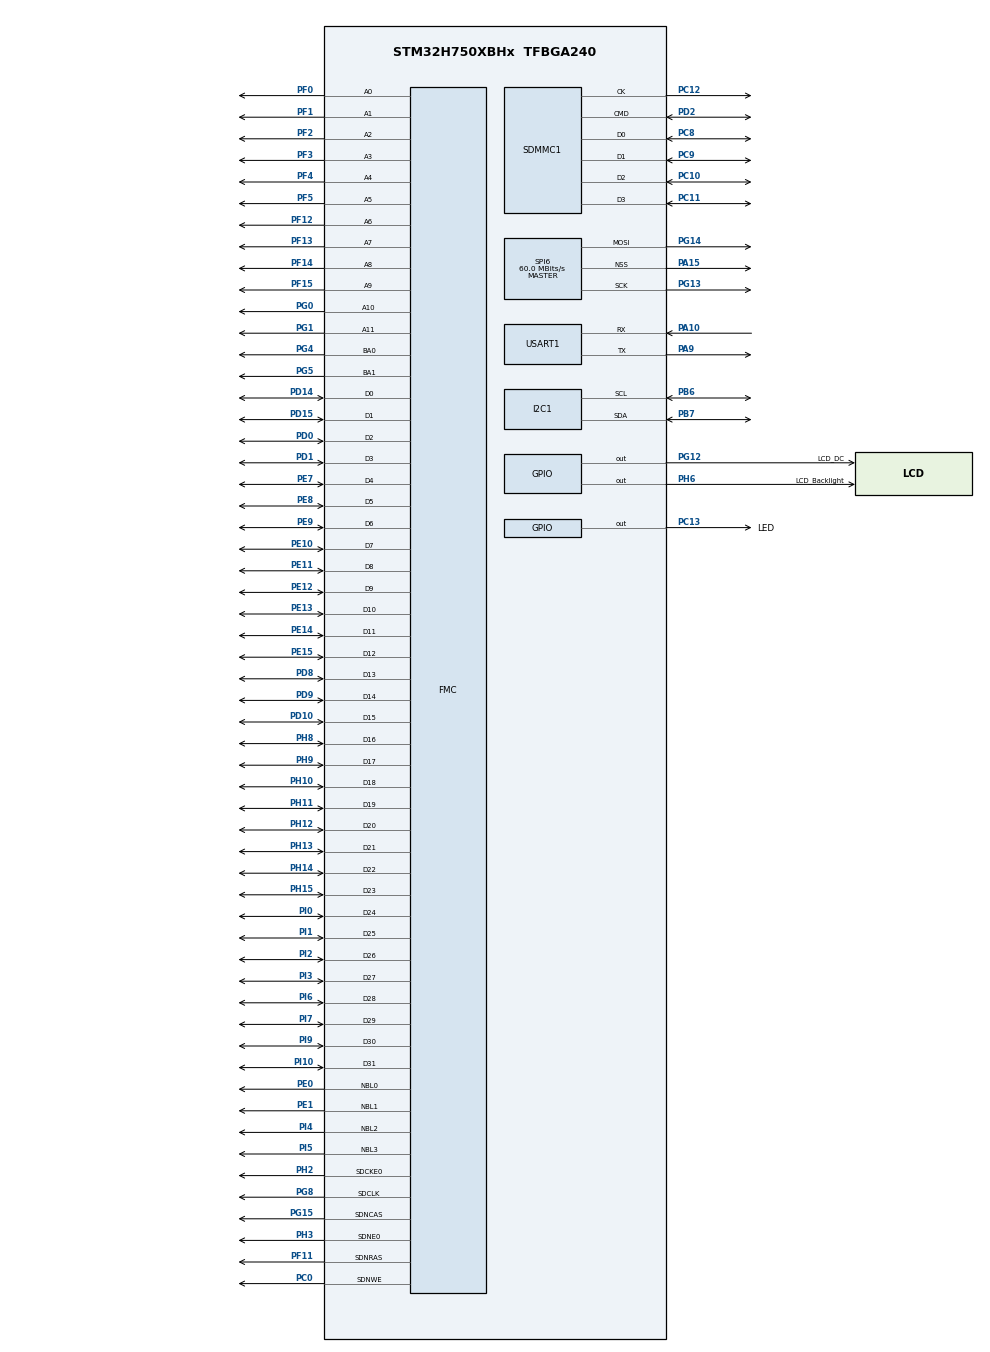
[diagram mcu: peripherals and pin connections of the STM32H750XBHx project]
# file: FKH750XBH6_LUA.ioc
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CORTEX_M7.AccessPermission_S-Cortex_Memory_Protection_Unit_Region1_Settings_S=MPU_REGION_FULL_ACCESS
CORTEX_M7.AccessPermission_S-Cortex_Memory_Protection_Unit_Region2_Settings_S=MPU_REGION_FULL_ACCESS
CORTEX_M7.AccessPermission_S-Cortex_Memory_Protection_Unit_Region3_Settings_S=MPU_REGION_FULL_ACCESS
CORTEX_M7.AccessPermission_Spec=MPU_REGION_FULL_ACCESS
CORTEX_M7.BaseAddress_S-Cortex_Memory_Protection_Unit_Region1_Settings_S=0x24000000
CORTEX_M7.BaseAddress_S-Cortex_Memory_Protection_Unit_Region2_Settings_S=0x90000000
CORTEX_M7.BaseAddress_S-Cortex_Memory_Protection_Unit_Region3_Settings_S=0xC0000000
CORTEX_M7.BaseAddress_Spec=0x20000000
CORTEX_M7.CPU_DCache=Enabled
CORTEX_M7.CPU_ICache=Enabled
CORTEX_M7.DisableExec_S-Cortex_Memory_Protection_Unit_Region2_Settings_S=MPU_INSTRUCTION_ACCESS_ENABLE
CORTEX_M7.DisableExec_Spec=MPU_INSTRUCTION_ACCESS_ENABLE
CORTEX_M7.Enable_S-Cortex_Memory_Protection_Unit_Region1_Settings_S=MPU_REGION_ENABLE
CORTEX_M7.Enable_S-Cortex_Memory_Protection_Unit_Region2_Settings_S=MPU_REGION_ENABLE
CORTEX_M7.Enable_S-Cortex_Memory_Protection_Unit_Region3_Settings_S=MPU_REGION_ENABLE
CORTEX_M7.IsBufferable_S-Cortex_Memory_Protection_Unit_Region1_Settings_S=MPU_ACCESS_BUFFERABLE
CORTEX_M7.IsBufferable_S-Cortex_Memory_Protection_Unit_Region2_Settings_S=MPU_ACCESS_NOT_BUFFERABLE
CORTEX_M7.IsBufferable_S-Cortex_Memory_Protection_Unit_Region3_Settings_S=MPU_ACCESS_BUFFERABLE
CORTEX_M7.IsBufferable_Spec=MPU_ACCESS_BUFFERABLE
CORTEX_M7.IsCacheable_S-Cortex_Memory_Protection_Unit_Region1_Settings_S=MPU_ACCESS_CACHEABLE
CORTEX_M7.IsCacheable_S-Cortex_Memory_Protection_Unit_Region2_Settings_S=MPU_ACCESS_CACHEABLE
CORTEX_M7.IsCacheable_S-Cortex_Memory_Protection_Unit_Region3_Settings_S=MPU_ACCESS_CACHEABLE
CORTEX_M7.IsCacheable_Spec=MPU_ACCESS_NOT_CACHEABLE
CORTEX_M7.IsShareable_S-Cortex_Memory_Protection_Unit_Region1_Settings_S=MPU_ACCESS_SHAREABLE
CORTEX_M7.IsShareable_S-Cortex_Memory_Protection_Unit_Region2_Settings_S=MPU_ACCESS_NOT_SHAREABLE
CORTEX_M7.IsShareable_S-Cortex_Memory_Protection_Unit_Region3_Settings_S=MPU_ACCESS_SHAREABLE
CORTEX_M7.IsShareable_Spec=MPU_ACCESS_NOT_SHAREABLE
CORTEX_M7.Size_S-Cortex_Memory_Protection_Unit_Region1_Settings_S=MPU_REGION_SIZE_512KB
CORTEX_M7.Size_S-Cortex_Memory_Protection_Unit_Region2_Settings_S=MPU_REGION_SIZE_32MB
CORTEX_M7.Size_S-Cortex_Memory_Protection_Unit_Region3_Settings_S=MPU_REGION_SIZE_32MB
CORTEX_M7.Size_Spec=MPU_REGION_SIZE_128KB
CORTEX_M7.SubRegionDisable_Spec=0x00
CORTEX_M7.TypeExtField_S-Cortex_Memory_Protection_Unit_Region1_Settings_S=MPU_TEX_LEVEL1
CORTEX_M7.TypeExtField_S-Cortex_Memory_Protection_Unit_Region3_Settings_S=MPU_TEX_LEVEL1
CORTEX_M7.TypeExtField_Spec=MPU_TEX_LEVEL1
CORTEX_M7.default_mode_Activation=1
Dma.Request0=USART1_RX
Dma.Request1=USART1_TX
Dma.USART1_RX.0.Direction=DMA_PERIPH_TO_MEMORY
Dma.USART1_RX.0.EventEnable=DISABLE
Dma.USART1_RX.0.FIFOMode=DMA_FIFOMODE_DISABLE
Dma.USART1_RX.0.Instance=DMA1_Stream0
Dma.USART1_RX.0.MemDataAlignment=DMA_MDATAALIGN_BYTE
Dma.USART1_RX.0.MemInc=DMA_MINC_ENABLE
Dma.USART1_RX.0.Mode=DMA_NORMAL
Dma.USART1_RX.0.PeriphDataAlignment=DMA_PDATAALIGN_BYTE
Dma.USART1_RX.0.PeriphInc=DMA_PINC_DISABLE
Dma.USART1_RX.0.Polarity=HAL_DMAMUX_REQ_GEN_RISING
Dma.USART1_RX.0.Priority=DMA_PRIORITY_HIGH
Dma.USART1_RX.0.RequestNumber=1
Dma.USART1_RX.0.SignalID=NONE
Dma.USART1_RX.0.SyncEnable=DISABLE
Dma.USART1_RX.0.SyncPolarity=HAL_DMAMUX_SYNC_NO_EVENT
Dma.USART1_RX.0.SyncRequestNumber=1
Dma.USART1_RX.0.SyncSignalID=NONE
Dma.USART1_TX.1.Direction=DMA_MEMORY_TO_PERIPH
Dma.USART1_TX.1.EventEnable=DISABLE
Dma.USART1_TX.1.FIFOMode=DMA_FIFOMODE_DISABLE
Dma.USART1_TX.1.Instance=DMA1_Stream1
Dma.USART1_TX.1.MemDataAlignment=DMA_MDATAALIGN_BYTE
Dma.USART1_TX.1.MemInc=DMA_MINC_ENABLE
Dma.USART1_TX.1.Mode=DMA_NORMAL
Dma.USART1_TX.1.PeriphDataAlignment=DMA_PDATAALIGN_BYTE
Dma.USART1_TX.1.PeriphInc=DMA_PINC_DISABLE
Dma.USART1_TX.1.Polarity=HAL_DMAMUX_REQ_GEN_RISING
Dma.USART1_TX.1.Priority=DMA_PRIORITY_HIGH
Dma.USART1_TX.1.RequestNumber=1
Dma.USART1_TX.1.SignalID=NONE
Dma.USART1_TX.1.SyncEnable=DISABLE
Dma.USART1_TX.1.SyncPolarity=HAL_DMAMUX_SYNC_NO_EVENT
Dma.USART1_TX.1.SyncRequestNumber=1
Dma.USART1_TX.1.SyncSignalID=NONE
FATFS._CODE_PAGE=437
FATFS._FS_RPATH=2
FATFS._MAX_SS=4096
FATFS._USE_LFN=2
FMC.CASLatency1=FMC_SDRAM_CAS_LATENCY_3
FMC.ColumnBitsNumber1=FMC_SDRAM_COLUMN_BITS_NUM_9
FMC.ExitSelfRefreshDelay1=6
FMC.LoadToActiveDelay1=2
FMC.RCDDelay1=2
FMC.RPDelay1=2
FMC.RPDelay2=2
FMC.ReadBurst1=FMC_SDRAM_RBURST_ENABLE
FMC.ReadBurst2=FMC_SDRAM_RBURST_ENABLE
FMC.RowCycleDelay1=7
FMC.RowCycleDelay2=7
FMC.SDClockPeriod1=FMC_SDRAM_CLOCK_PERIOD_2
FMC.SDClockPeriod2=FMC_SDRAM_CLOCK_PERIOD_2
FMC.SelfRefreshTime1=4
FMC.WriteRecoveryTime1=3
FREERTOS.HEAP_NUMBER=5
FREERTOS.Tasks01=defaultTask,24,128,StartDefaultTask,Default,NULL,Dynamic,NULL,NULL;LUA_ProcessTask,24,512,LUA_ProcessTask_Handle,Default,NULL,Dynamic,NULL,NULL
FREERTOS.configENABLE_FPU=1
FREERTOS.configGENERATE_RUN_TIME_STATS=1
FREERTOS.configRECORD_STACK_HIGH_ADDRESS=1
I2C1.Timing=0x307075B1
Mcu.Family=STM32H7
Mcu.Name=STM32H750XBHx
Mcu.Package=TFBGA240
Mdma.MDMA_Channel0.Request0=SDMMC1_END_DATA
Mdma.MDMA_Channel0.RequestsNb=1
Mdma.MDMA_Channel0.SDMMC1_END_DATA.0.BlockCount=0
Mdma.MDMA_Channel0.SDMMC1_END_DATA.0.BlockDataLength=0
Mdma.MDMA_Channel0.SDMMC1_END_DATA.0.BufferTransferLength=1
Mdma.MDMA_Channel0.SDMMC1_END_DATA.0.CircularMode=MDMA_LINEAR_LIST
Mdma.MDMA_Channel0.SDMMC1_END_DATA.0.DataAlignment=MDMA_DATAALIGN_PACKENABLE
Mdma.MDMA_Channel0.SDMMC1_END_DATA.0.DestBlockAddressOffset=0
Mdma.MDMA_Channel0.SDMMC1_END_DATA.0.DestBurst=MDMA_DEST_BURST_SINGLE
Mdma.MDMA_Channel0.SDMMC1_END_DATA.0.DestDataSize=MDMA_DEST_DATASIZE_BYTE
Mdma.MDMA_Channel0.SDMMC1_END_DATA.0.DestinationInc=MDMA_DEST_INC_BYTE
Mdma.MDMA_Channel0.SDMMC1_END_DATA.0.DstAddress=0
Mdma.MDMA_Channel0.SDMMC1_END_DATA.0.Endianness=MDMA_LITTLE_ENDIANNESS_PRESERVE
Mdma.MDMA_Channel0.SDMMC1_END_DATA.0.Instance=MDMA_Channel0
Mdma.MDMA_Channel0.SDMMC1_END_DATA.0.MaskAddress=0
Mdma.MDMA_Channel0.SDMMC1_END_DATA.0.MaskData=0
Mdma.MDMA_Channel0.SDMMC1_END_DATA.0.Priority=MDMA_PRIORITY_MEDIUM
Mdma.MDMA_Channel0.SDMMC1_END_DATA.0.Rank=First
Mdma.MDMA_Channel0.SDMMC1_END_DATA.0.SourceBlockAddressOffset=0
Mdma.MDMA_Channel0.SDMMC1_END_DATA.0.SourceBurst=MDMA_SOURCE_BURST_SINGLE
Mdma.MDMA_Channel0.SDMMC1_END_DATA.0.SourceDataSize=MDMA_SRC_DATASIZE_BYTE
Mdma.MDMA_Channel0.SDMMC1_END_DATA.0.SourceInc=MDMA_SRC_INC_BYTE
Mdma.MDMA_Channel0.SDMMC1_END_DATA.0.SrcAddress=0
Mdma.MDMA_Channel0.SDMMC1_END_DATA.0.TransferTriggerMode=MDMA_BUFFER_TRANSFER
Mdma.RequestSet0=MDMA_Channel0
Mdma.RequestSetsNb=1
NVIC.DMA1_Stream0_IRQn=true\:5\:0\:false\:false\:true\:true\:false\:true\:true
NVIC.DMA1_Stream1_IRQn=true\:5\:0\:false\:false\:true\:true\:false\:true\:true
NVIC.MDMA_IRQn=true\:5\:0\:false\:false\:true\:false\:false\:true\:true
NVIC.PriorityGroup=NVIC_PRIORITYGROUP_4
NVIC.SDMMC1_IRQn=true\:5\:0\:false\:false\:true\:true\:true\:true\:true
NVIC.TIM17_IRQn=true\:15\:0\:false\:false\:true\:false\:false\:true\:true
NVIC.TimeBase=TIM17_IRQn
NVIC.TimeBaseIP=TIM17
NVIC.USART1_IRQn=true\:5\:0\:false\:false\:true\:true\:false\:true\:true
PA10.GPIO_Speed=GPIO_SPEED_FREQ_VERY_HIGH
PA10.Mode=Asynchronous
PA10.Signal=USART1_RX
PA15\ (JTDI).GPIO_Speed=GPIO_SPEED_FREQ_VERY_HIGH
PA15\ (JTDI).Mode=NSS_Signal_Hard_Output
PA15\ (JTDI).Signal=SPI6_NSS
PA9.GPIO_Speed=GPIO_SPEED_FREQ_VERY_HIGH
PA9.Mode=Asynchronous
PA9.Signal=USART1_TX
PB6.GPIO_Speed=GPIO_SPEED_FREQ_VERY_HIGH
PB6.Mode=I2C
PB6.Signal=I2C1_SCL
PB7.GPIO_Speed=GPIO_SPEED_FREQ_VERY_HIGH
PB7.Mode=I2C
PB7.Signal=I2C1_SDA
PC0.Signal=FMC_SDNWE
PC10.Mode=SD_4_bits_Wide_bus
PC10.Signal=SDMMC1_D2
PC11.Mode=SD_4_bits_Wide_bus
PC11.Signal=SDMMC1_D3
PC12.Mode=SD_4_bits_Wide_bus
PC12.Signal=SDMMC1_CK
PC13.GPIO_Label=LED
PC13.PinState=GPIO_PIN_SET
PC13.Signal=GPIO_Output
PC14-OSC32_IN\ (OSC32_IN).Mode=LSE-External-Oscillator
PC14-OSC32_IN\ (OSC32_IN).Signal=RCC_OSC32_IN
PC15-OSC32_OUT\ (OSC32_OUT).Mode=LSE-External-Oscillator
PC15-OSC32_OUT\ (OSC32_OUT).Signal=RCC_OSC32_OUT
PC8.Mode=SD_4_bits_Wide_bus
PC8.Signal=SDMMC1_D0
PC9.Mode=SD_4_bits_Wide_bus
PC9.Signal=SDMMC1_D1
PD0.Signal=FMC_D2_DA2
PD1.Signal=FMC_D3_DA3
PD10.Signal=FMC_D15_DA15
PD14.Signal=FMC_D0_DA0
PD15.Signal=FMC_D1_DA1
PD2.Mode=SD_4_bits_Wide_bus
PD2.Signal=SDMMC1_CMD
PD8.Signal=FMC_D13_DA13
PD9.Signal=FMC_D14_DA14
PE0.Signal=FMC_NBL0
PE1.Signal=FMC_NBL1
PE10.Signal=FMC_D7_DA7
PE11.Signal=FMC_D8_DA8
PE12.Signal=FMC_D9_DA9
PE13.Signal=FMC_D10_DA10
PE14.Signal=FMC_D11_DA11
PE15.Signal=FMC_D12_DA12
PE7.Signal=FMC_D4_DA4
PE8.Signal=FMC_D5_DA5
PE9.Signal=FMC_D6_DA6
PF0.Signal=FMC_A0
PF1.Signal=FMC_A1
PF10.GPIO_Speed=GPIO_SPEED_FREQ_VERY_HIGH
PF10.Signal=QUADSPI_CLK
PF11.Signal=FMC_SDNRAS
PF12.Signal=FMC_A6
PF13.Signal=FMC_A7
PF14.Signal=FMC_A8
PF15.Signal=FMC_A9
PF2.Signal=FMC_A2
PF3.Signal=FMC_A3
PF4.Signal=FMC_A4
PF5.Signal=FMC_A5
PF6.GPIO_Speed=GPIO_SPEED_FREQ_VERY_HIGH
PF6.Signal=QUADSPI_BK1_IO3
PF7.GPIO_Speed=GPIO_SPEED_FREQ_VERY_HIGH
PF7.Signal=QUADSPI_BK1_IO2
PF8.GPIO_Speed=GPIO_SPEED_FREQ_VERY_HIGH
PF8.Signal=QUADSPI_BK1_IO0
PF9.GPIO_Speed=GPIO_SPEED_FREQ_VERY_HIGH
PF9.Signal=QUADSPI_BK1_IO1
PG0.Signal=FMC_A10
PG1.Signal=FMC_A11
PG12.GPIO_Label=LCD_DC
PG12.GPIO_Speed=GPIO_SPEED_FREQ_VERY_HIGH
PG12.Signal=GPIO_Output
PG13.GPIO_Speed=GPIO_SPEED_FREQ_VERY_HIGH
PG13.Mode=TX_Only_Simplex_Unidirect_Master
PG13.Signal=SPI6_SCK
PG14.GPIO_Speed=GPIO_SPEED_FREQ_VERY_HIGH
PG14.Mode=TX_Only_Simplex_Unidirect_Master
PG14.Signal=SPI6_MOSI
PG15.Signal=FMC_SDNCAS
PG4.Signal=FMC_A14_BA0
PG5.Signal=FMC_A15_BA1
PG6.GPIO_Speed=GPIO_SPEED_FREQ_VERY_HIGH
PG6.Signal=QUADSPI_BK1_NCS
PG8.Signal=FMC_SDCLK
PH0-OSC_IN\ (PH0).Mode=HSE-External-Oscillator
PH0-OSC_IN\ (PH0).Signal=RCC_OSC_IN
PH1-OSC_OUT\ (PH1).Mode=HSE-External-Oscillator
PH1-OSC_OUT\ (PH1).Signal=RCC_OSC_OUT
PH10.Signal=FMC_D18
PH11.Signal=FMC_D19
PH12.Signal=FMC_D20
PH13.Signal=FMC_D21
PH14.Signal=FMC_D22
PH15.Signal=FMC_D23
PH2.Mode=SdramChipSelect1_1
PH2.Signal=FMC_SDCKE0
PH3.Mode=SdramChipSelect1_1
PH3.Signal=FMC_SDNE0
PH6.GPIO_Label=LCD_Backlight
PH6.GPIO_Speed=GPIO_SPEED_FREQ_MEDIUM
PH6.Signal=GPIO_Output
PH8.Signal=FMC_D16
PH9.Signal=FMC_D17
PI0.Signal=FMC_D24
PI1.Signal=FMC_D25
PI10.Signal=FMC_D31
PI2.Signal=FMC_D26
PI3.Signal=FMC_D27
PI4.Signal=FMC_NBL2
PI5.Signal=FMC_NBL3
PI6.Signal=FMC_D28
PI7.Signal=FMC_D29
PI9.Signal=FMC_D30
ProjectManager.HeapSize=0x2000
ProjectManager.StackSize=0x400
ProjectManager.TargetToolchain=CMake
RCC.ADCFreq_Value=320000000
RCC.APB1Freq_Value=120000000
RCC.APB2Freq_Value=120000000
RCC.APB3Freq_Value=120000000
RCC.APB4Freq_Value=120000000
RCC.CortexFreq_Value=480000000
RCC.D1PPRE=RCC_APB3_DIV2
RCC.D2PPRE1=RCC_APB1_DIV2
RCC.D2PPRE2=RCC_APB2_DIV2
RCC.D3PPRE=RCC_APB4_DIV2
RCC.DIVM1=5
RCC.DIVM2=5
RCC.DIVM3=5
RCC.DIVN1=192
RCC.DIVN2=128
RCC.DIVN3=128
RCC.DIVQ1=4
RCC.HCLKFreq_Value=240000000
RCC.HPRE=RCC_HCLK_DIV2
RCC.PLLSourceVirtual=RCC_PLLSOURCE_HSE
RCC.SYSCLKFreq_VALUE=480000000
RCC.SYSCLKSource=RCC_SYSCLKSOURCE_PLLCLK
RCC.USBFreq_Value=240000000
SDMMC1.ClockDiv=6
SH.FMC_A0.0=FMC_A0,12b-sda1
SH.FMC_A1.0=FMC_A1,12b-sda1
SH.FMC_A10.0=FMC_A10,12b-sda1
SH.FMC_A11.0=FMC_A11,12b-sda1
SH.FMC_A14_BA0.0=FMC_BA0,FourSdramBanks1
SH.FMC_A15_BA1.0=FMC_BA1,FourSdramBanks1
SH.FMC_A2.0=FMC_A2,12b-sda1
SH.FMC_A3.0=FMC_A3,12b-sda1
SH.FMC_A4.0=FMC_A4,12b-sda1
SH.FMC_A5.0=FMC_A5,12b-sda1
SH.FMC_A6.0=FMC_A6,12b-sda1
SH.FMC_A7.0=FMC_A7,12b-sda1
SH.FMC_A8.0=FMC_A8,12b-sda1
SH.FMC_A9.0=FMC_A9,12b-sda1
SH.FMC_D0_DA0.0=FMC_D0,sd-32b-d1
SH.FMC_D10_DA10.0=FMC_D10,sd-32b-d1
SH.FMC_D11_DA11.0=FMC_D11,sd-32b-d1
SH.FMC_D12_DA12.0=FMC_D12,sd-32b-d1
SH.FMC_D13_DA13.0=FMC_D13,sd-32b-d1
SH.FMC_D14_DA14.0=FMC_D14,sd-32b-d1
SH.FMC_D15_DA15.0=FMC_D15,sd-32b-d1
SH.FMC_D16.0=FMC_D16,sd-32b-d1
SH.FMC_D17.0=FMC_D17,sd-32b-d1
SH.FMC_D18.0=FMC_D18,sd-32b-d1
SH.FMC_D19.0=FMC_D19,sd-32b-d1
SH.FMC_D1_DA1.0=FMC_D1,sd-32b-d1
SH.FMC_D20.0=FMC_D20,sd-32b-d1
SH.FMC_D21.0=FMC_D21,sd-32b-d1
SH.FMC_D22.0=FMC_D22,sd-32b-d1
SH.FMC_D23.0=FMC_D23,sd-32b-d1
SH.FMC_D24.0=FMC_D24,sd-32b-d1
SH.FMC_D25.0=FMC_D25,sd-32b-d1
SH.FMC_D26.0=FMC_D26,sd-32b-d1
SH.FMC_D27.0=FMC_D27,sd-32b-d1
SH.FMC_D28.0=FMC_D28,sd-32b-d1
SH.FMC_D29.0=FMC_D29,sd-32b-d1
SH.FMC_D2_DA2.0=FMC_D2,sd-32b-d1
SH.FMC_D30.0=FMC_D30,sd-32b-d1
SH.FMC_D31.0=FMC_D31,sd-32b-d1
SH.FMC_D3_DA3.0=FMC_D3,sd-32b-d1
SH.FMC_D4_DA4.0=FMC_D4,sd-32b-d1
SH.FMC_D5_DA5.0=FMC_D5,sd-32b-d1
SH.FMC_D6_DA6.0=FMC_D6,sd-32b-d1
SH.FMC_D7_DA7.0=FMC_D7,sd-32b-d1
SH.FMC_D8_DA8.0=FMC_D8,sd-32b-d1
SH.FMC_D9_DA9.0=FMC_D9,sd-32b-d1
SH.FMC_NBL0.0=FMC_NBL0,Sd4ByteEnable1
SH.FMC_NBL1.0=FMC_NBL1,Sd4ByteEnable1
SH.FMC_NBL2.0=FMC_NBL2,Sd4ByteEnable1
SH.FMC_NBL3.0=FMC_NBL3,Sd4ByteEnable1
SH.FMC_SDCLK.0=FMC_SDCLK,12b-sda1
SH.FMC_SDNCAS.0=FMC_SDNCAS,12b-sda1
SH.FMC_SDNRAS.0=FMC_SDNRAS,12b-sda1
SH.FMC_SDNWE.0=FMC_SDNWE,12b-sda1
SPI6.CalculateBaudRate=60.0 MBits/s
SPI6.DataSize=SPI_DATASIZE_8BIT
SPI6.Direction=SPI_DIRECTION_2LINES_TXONLY
SPI6.FifoThreshold=SPI_FIFO_THRESHOLD_02DATA
SPI6.Mode=SPI_MODE_MASTER
SPI6.VirtualNSS=VM_NSSHARD
SPI6.VirtualType=VM_MASTER
USART1.VirtualMode-Asynchronous=VM_ASYNC
VP_FATFS_VS_SDIO.Mode=SDIO
VP_FREERTOS_VS_CMSIS_V2.Mode=CMSIS_V2
VP_MEMORYMAP_VS_MEMORYMAP.Mode=CurAppReg
VP_SYS_VS_tim17.Mode=TIM17
board=custom

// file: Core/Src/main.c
/* USER CODE BEGIN Header */
/**
  ******************************************************************************
  * @file           : main.c
  * @brief          : Main program body
  ******************************************************************************
  * @attention
  *
  * Copyright (c) 2025 STMicroelectronics.
  * All rights reserved.
  *
  * This software is licensed under terms that can be found in the LICENSE file
  * in the root directory of this software component.
  * If no LICENSE file comes with this software, it is provided AS-IS.
  *
  ******************************************************************************
  */
/* USER CODE END Header */
#include "main.h"
#include "cmsis_os.h"
#include "dma.h"
#include "fatfs.h"
#include "i2c.h"
#include "mdma.h"
#include "sdmmc.h"
#include "spi.h"
#include "usart.h"
#include "gpio.h"
#include "fmc.h"

void SystemClock_Config(void);
static void MPU_Config(void);
void MX_FREERTOS_Init(void);

int main(void)
{

  /* USER CODE BEGIN 1 */
  __enable_irq();
  /* USER CODE END 1 */

  /* MPU Configuration--------------------------------------------------------*/
  MPU_Config();

  /* Enable the CPU Cache */

  /* Enable I-Cache---------------------------------------------------------*/
  SCB_EnableICache();

  /* Enable D-Cache---------------------------------------------------------*/
  SCB_EnableDCache();

  /* MCU Configuration--------------------------------------------------------*/

  /* Reset of all peripherals, Initializes the Flash interface and the Systick. */
  HAL_Init();

  /* Configure the system clock */
  SystemClock_Config();

  /* Initialize all configured peripherals */
  MX_GPIO_Init();
  MX_DMA_Init();
  MX_MDMA_Init();
  MX_USART1_UART_Init();
  MX_I2C1_Init();
  MX_SDMMC1_SD_Init();
  MX_SPI6_Init();
  MX_FATFS_Init();
  MX_FMC_Init();
  /* USER CODE BEGIN 2 */
  // if(QSPI_W25Qxx_MemoryMappedMode() != QSPI_W25Qxx_OK)
  //   Error_Handler();
  /* USER CODE END 2 */

  /* Init scheduler */
  osKernelInitialize();  /* Call init function for freertos objects (in cmsis_os2.c) */
  MX_FREERTOS_Init();

  /* Start scheduler */
  osKernelStart();

  /* We should never get here as control is now taken by the scheduler */

  /* Infinite loop */
  while (1)
  {

  }
}

void SystemClock_Config(void)
{
  RCC_OscInitTypeDef RCC_OscInitStruct = {0};
  RCC_ClkInitTypeDef RCC_ClkInitStruct = {0};

  /** Supply configuration update enable
  */
  HAL_PWREx_ConfigSupply(PWR_LDO_SUPPLY);

  /** Configure the main internal regulator output voltage
  */
  __HAL_PWR_VOLTAGESCALING_CONFIG(PWR_REGULATOR_VOLTAGE_SCALE0);

  while(!__HAL_PWR_GET_FLAG(PWR_FLAG_VOSRDY)) {}

  /** Initializes the RCC Oscillators according to the specified parameters
  * in the RCC_OscInitTypeDef structure.
  */
  RCC_OscInitStruct.OscillatorType = RCC_OSCILLATORTYPE_HSE;
  RCC_OscInitStruct.HSEState = RCC_HSE_ON;
  RCC_OscInitStruct.PLL.PLLState = RCC_PLL_ON;
  RCC_OscInitStruct.PLL.PLLSource = RCC_PLLSOURCE_HSE;
  RCC_OscInitStruct.PLL.PLLM = 5;
  RCC_OscInitStruct.PLL.PLLN = 192;
  RCC_OscInitStruct.PLL.PLLP = 2;
  RCC_OscInitStruct.PLL.PLLQ = 4;
  RCC_OscInitStruct.PLL.PLLR = 2;
  RCC_OscInitStruct.PLL.PLLRGE = RCC_PLL1VCIRANGE_2;
  RCC_OscInitStruct.PLL.PLLVCOSEL = RCC_PLL1VCOWIDE;
  RCC_OscInitStruct.PLL.PLLFRACN = 0;
  if (HAL_RCC_OscConfig(&RCC_OscInitStruct) != HAL_OK)
  {
    Error_Handler();
  }

  /** Initializes the CPU, AHB and APB buses clocks
  */
  RCC_ClkInitStruct.ClockType = RCC_CLOCKTYPE_HCLK|RCC_CLOCKTYPE_SYSCLK
                              |RCC_CLOCKTYPE_PCLK1|RCC_CLOCKTYPE_PCLK2
                              |RCC_CLOCKTYPE_D3PCLK1|RCC_CLOCKTYPE_D1PCLK1;
  RCC_ClkInitStruct.SYSCLKSource = RCC_SYSCLKSOURCE_PLLCLK;
  RCC_ClkInitStruct.SYSCLKDivider = RCC_SYSCLK_DIV1;
  RCC_ClkInitStruct.AHBCLKDivider = RCC_HCLK_DIV2;
  RCC_ClkInitStruct.APB3CLKDivider = RCC_APB3_DIV2;
  RCC_ClkInitStruct.APB1CLKDivider = RCC_APB1_DIV2;
  RCC_ClkInitStruct.APB2CLKDivider = RCC_APB2_DIV2;
  RCC_ClkInitStruct.APB4CLKDivider = RCC_APB4_DIV2;

  if (HAL_RCC_ClockConfig(&RCC_ClkInitStruct, FLASH_LATENCY_4) != HAL_OK)
  {
    Error_Handler();
  }
}

 /* MPU Configuration */

void MPU_Config(void)
{
  MPU_Region_InitTypeDef MPU_InitStruct = {0};

  /* Disables the MPU */
  HAL_MPU_Disable();

  /** Initializes and configures the Region and the memory to be protected
  */
  MPU_InitStruct.Enable = MPU_REGION_ENABLE;
  MPU_InitStruct.Number = MPU_REGION_NUMBER0;
  MPU_InitStruct.BaseAddress = 0x20000000;
  MPU_InitStruct.Size = MPU_REGION_SIZE_128KB;
  MPU_InitStruct.SubRegionDisable = 0x00;
  MPU_InitStruct.TypeExtField = MPU_TEX_LEVEL1;
  MPU_InitStruct.AccessPermission = MPU_REGION_FULL_ACCESS;
  MPU_InitStruct.DisableExec = MPU_INSTRUCTION_ACCESS_ENABLE;
  MPU_InitStruct.IsShareable = MPU_ACCESS_NOT_SHAREABLE;
  MPU_InitStruct.IsCacheable = MPU_ACCESS_NOT_CACHEABLE;
  MPU_InitStruct.IsBufferable = MPU_ACCESS_BUFFERABLE;

  HAL_MPU_ConfigRegion(&MPU_InitStruct);

  /** Initializes and configures the Region and the memory to be protected
  */
  MPU_InitStruct.Number = MPU_REGION_NUMBER1;
  MPU_InitStruct.BaseAddress = 0x24000000;
  MPU_InitStruct.Size = MPU_REGION_SIZE_512KB;
  MPU_InitStruct.SubRegionDisable = 0x0;
  MPU_InitStruct.IsShareable = MPU_ACCESS_SHAREABLE;
  MPU_InitStruct.IsCacheable = MPU_ACCESS_CACHEABLE;

  HAL_MPU_ConfigRegion(&MPU_InitStruct);

  /** Initializes and configures the Region and the memory to be protected
  */
  MPU_InitStruct.Number = MPU_REGION_NUMBER2;
  MPU_InitStruct.BaseAddress = 0x90000000;
  MPU_InitStruct.Size = MPU_REGION_SIZE_32MB;
  MPU_InitStruct.TypeExtField = MPU_TEX_LEVEL0;
  MPU_InitStruct.IsShareable = MPU_ACCESS_NOT_SHAREABLE;
  MPU_InitStruct.IsBufferable = MPU_ACCESS_NOT_BUFFERABLE;

  HAL_MPU_ConfigRegion(&MPU_InitStruct);

  /** Initializes and configures the Region and the memory to be protected
  */
  MPU_InitStruct.Number = MPU_REGION_NUMBER3;
  MPU_InitStruct.BaseAddress = 0xC0000000;
  MPU_InitStruct.TypeExtField = MPU_TEX_LEVEL1;
  MPU_InitStruct.IsShareable = MPU_ACCESS_SHAREABLE;
  MPU_InitStruct.IsBufferable = MPU_ACCESS_BUFFERABLE;

  HAL_MPU_ConfigRegion(&MPU_InitStruct);
  /* Enables the MPU */
  HAL_MPU_Enable(MPU_PRIVILEGED_DEFAULT);

}

void HAL_TIM_PeriodElapsedCallback(TIM_HandleTypeDef *htim)
{
  if (htim->Instance == TIM17)
  {
    HAL_IncTick();
  }
}

void Error_Handler(void)
{
  __disable_irq();
  while (1)
  {
  }
}

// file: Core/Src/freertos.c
/* USER CODE BEGIN Header */
/**
  ******************************************************************************
  * File Name          : freertos.c
  * Description        : Code for freertos applications
  ******************************************************************************
  * @attention
  *
  * Copyright (c) 2025 STMicroelectronics.
  * All rights reserved.
  *
  * This software is licensed under terms that can be found in the LICENSE file
  * in the root directory of this software component.
  * If no LICENSE file comes with this software, it is provided AS-IS.
  *
  ******************************************************************************
  */
/* USER CODE END Header */

#include "FreeRTOS.h"
#include "task.h"
#include "main.h"
#include "cmsis_os.h"

/* USER CODE BEGIN Includes */
#include "usart.h"
#include "sdmmc.h"
#include "terminal.h"
#include "uart_dyn_rx.h"
#include <stdlib.h>
#include <string.h>
#include <sys/_intsup.h>

#include "lua.h"
#include "lualib.h"
#include "portable.h"
#include "setjmp.h"
#include "fatfs.h"
#include "config.h"
// #include "embedded_lua.h"
#include "hardware_bindings.h"
#include "lua_file_execute.h"
#include "lua_fatfs.h"
#include "lua_display.h"
/* USER CODE END Includes */

/* USER CODE BEGIN PTD */
#define AUTO_MOUNT 1
#define AUTO_INIT_DISPLAY 1
/* USER CODE END PTD */

/* USER CODE BEGIN PD */
// #define DTCMRAM_ADDR       ((uint8_t*)0x20000000)
// #define DTCMRAM_SIZE       ((uint32_t)0x00010000)
#define AXIRAM_ADDR        ((uint8_t*)0x24002000)
#define AXIRAM_SIZE        ((uint32_t)0x00078000)
#define SDRAM_ADDR         ((uint8_t*)0xC0000000)
#define SDRAM_SIZE         ((uint32_t)0x02000000)
/* USER CODE END PD */

/* USER CODE BEGIN Variables */
// static jmp_buf g_lua_panic_jmp;

static HeapRegion_t HeapRAMRegions[]=
{
  // {DTCMRAM_ADDR, DTCMRAM_SIZE},
  {AXIRAM_ADDR, AXIRAM_SIZE},
  {SDRAM_ADDR, SDRAM_SIZE},
  {NULL,0}
};
/* USER CODE END Variables */
/* Definitions for defaultTask */
osThreadId_t defaultTaskHandle;
const osThreadAttr_t defaultTask_attributes = {
  .name = "defaultTask",
  .stack_size = 128 * 4,
  .priority = (osPriority_t) osPriorityNormal,
};
/* Definitions for LUA_ProcessTask */
osThreadId_t LUA_ProcessTaskHandle;
const osThreadAttr_t LUA_ProcessTask_attributes = {
  .name = "LUA_ProcessTask",
  .stack_size = 2048 * 4,
  .priority = (osPriority_t) osPriorityNormal,
};

/* USER CODE BEGIN FunctionPrototypes */
int lua_panic_handler(lua_State* L);
int safe_lua_execute(lua_State* L, const char* code, const char* cmd_name);

void FatFs_GetVolume(void);
void FatFS_FileList(char* path);
uint8_t FatFs_FileTest(void);
/* USER CODE END FunctionPrototypes */

void StartDefaultTask(void *argument);
void LUA_ProcessTask_Handle(void *argument);

void MX_FREERTOS_Init(void); /* (MISRA C 2004 rule 8.1) */

/* Hook prototypes */
void configureTimerForRunTimeStats(void);
unsigned long getRunTimeCounterValue(void);

/* USER CODE BEGIN 1 */
/* Functions needed when configGENERATE_RUN_TIME_STATS is on */
void configureTimerForRunTimeStats(void)
{
	/* 启用 DWT 功能 */
  CoreDebug->DEMCR |= CoreDebug_DEMCR_TRCENA_Msk;

  /* 重置并启用周期计数器 */
  DWT->CYCCNT = 0;
  DWT->CTRL |= DWT_CTRL_CYCCNTENA_Msk;
}

unsigned long getRunTimeCounterValue(void)
{
	/* 直接返回当前周期计数值 */
  return DWT->CYCCNT;
}
/* USER CODE END 1 */

void MX_FREERTOS_Init(void) {
  /* USER CODE BEGIN Init */
  vPortDefineHeapRegions(HeapRAMRegions);
  /* USER CODE END Init */

  /* Create the thread(s) */
  /* creation of defaultTask */
  defaultTaskHandle = osThreadNew(StartDefaultTask, NULL, &defaultTask_attributes);

  /* creation of LUA_ProcessTask */
  LUA_ProcessTaskHandle = osThreadNew(LUA_ProcessTask_Handle, NULL, &LUA_ProcessTask_attributes);

}

void StartDefaultTask(void *argument)
{
  /* USER CODE BEGIN StartDefaultTask */
  // safe_printf("\rThread run\n");
  void *axi_sram_ptr = pvPortMalloc(100);
  if(axi_sram_ptr) {
      safe_printf("\r\033[35mSRAM allocation test: PASS (0x%lX)\033[0m\r\n", axi_sram_ptr);
      vPortFree(axi_sram_ptr);
  } else {
      safe_printf("\r\033[31mSRAM allocation test: FAIL\033[0m\r\n");
  }
  void *sdram_ptr = pvPortMalloc(1024 * 1024);  // 1MB
  if(sdram_ptr) {
      safe_printf("\r\033[35mSDRAM allocation test: PASS (0x%lX)\033[0m\r\n", sdram_ptr);

      /* 验证确实在 SDRAM 地址范围内 */
      if((uint32_t)sdram_ptr >= (uint32_t)SDRAM_ADDR &&
         (uint32_t)sdram_ptr < (uint32_t)SDRAM_ADDR + SDRAM_SIZE) {
          safe_printf("\r\033[35mSDRAM address verification: PASS (0x%lX)\033[0m\r\n", sdram_ptr);
      } else {
          safe_printf("\r\033[35mSDRAM address verification: FAIL (0x%lX)\033[0m\r\n", sdram_ptr);
      }
      vPortFree(sdram_ptr);
  } else {
      safe_printf("\r\033[31mSDRAM allocation test: FAIL\033[0m\r\n");
  }
  /* Infinite loop */
  for(;;)
  {
    osDelay(1);
  }
  /* USER CODE END StartDefaultTask */
}

void LUA_ProcessTask_Handle(void *argument)
{
  /* USER CODE BEGIN LUA_ProcessTask_Handle */
  /* Infinite loop */
  // UART_DataPacket_t packet;
  char* received_cmd = NULL;
  lua_State* L;
  // 创建Lua虚拟机（这个任务的私有资源）
  L = luaL_newstate();
  if (L == NULL) {
    vTaskDelete(NULL);
  }
  luaL_openlibs(L); // 打开基础库
  // embedded_lua_init();
  hardware_bindings_init(L); // 注册你的硬件API
  fatfs_bindings_init(L);
  display_bindings_init(L);
  #if AUTO_INIT_DISPLAY
  lua_display_init(L);
  #endif
  #if AUTO_MOUNT
  if(lua_fatfs_mount(L) == 0)
    lua_auto_execute_startup(L);
    // FatFs_FileTest();
  #endif
  Terminal_Init();
  // UART_Dynamic_Receive_Init();
  // safe_printf("\033[36mLua Shell> \033[0m");
  /* Infinite loop */
  for(;;)
  {
    //  if (xQueueReceive(UART_Receiver.packet_queue, &packet, portMAX_DELAY)) {
    //     // 直接转换并处理
    //     uint8_t* data_ptr = (uint8_t*)packet.data;
    //     data_ptr[packet.length] = '\0';  // 就地修改

    //     // 作为字符串处理
    //     safe_printf("%s\n", (char*)data_ptr);

    //     // Lua执行
    //     // lua_execute_command(L, (char*)data_ptr);

    //     // 新提示符
    //     safe_printf("\033[36mLua Shell> \033[0m");
    // }

    if (xQueueReceive(g_terminal.cmd_queue, &received_cmd, portMAX_DELAY)) {
      if (received_cmd != NULL) {
        // 打印原命令，调试可用
        // safe_printf("\r\nReceived command: %s\r\n", received_cmd);

        // TODO: 在这里添加命令解析和处理逻辑
        // 执行命令
        if(safe_lua_execute(L, received_cmd, received_cmd) == LUA_OK){
          safe_printf("\033[32m\r%s: Operation Sucess End\033[0m\r\n", received_cmd);
        }

        // 释放内存
        free(received_cmd);
        received_cmd = NULL;
        // 显示新的提示符
        safe_printf("\r\033[36m[Lua Shell]>\033[0m ");
      }
    }
    // osDelay(1);
  }
  /* USER CODE END LUA_ProcessTask_Handle */
}

/* USER CODE BEGIN Application */

//	函数：FatFs_FileTest
//	功能：进行文件写入和读取测试
//
uint8_t FatFs_FileTest(void)	//文件创建和写入测试
{
	uint8_t i = 0;
	uint16_t BufferSize = 0;
	FIL	MyFile;			// 文件对象
	UINT 	MyFile_Num;		//	数据长度
	BYTE 	MyFile_WriteBuffer[] = "STM32H750XBH6 SD卡 文件系统测试";	//要写入的数据
	BYTE 	MyFile_ReadBuffer[1024];	//要读出的数据
  uint8_t MyFile_Res;

	safe_printf("-------------FatFs File Create and Read/Write Test---------------\r\n");

	if(f_open(&MyFile,"0:FatFs Test.txt",FA_CREATE_ALWAYS | FA_WRITE) == FR_OK) //打开文件，若不存在则创建该文件
	{
		safe_printf("File Open/Create Sucess,Ready Write Data...\r\n");

		if (f_write(&MyFile,MyFile_WriteBuffer,sizeof(MyFile_WriteBuffer),&MyFile_Num) == FR_OK)	//向文件写入数据
		{
			safe_printf("Write Sucess,Write Content\r\n");
			safe_printf("%s\r\n",MyFile_WriteBuffer);
		}
		else
		{
			safe_printf("Failed to write file. Please check the SD card or reformat it!\r\n");
			f_close(&MyFile);	  //关闭文件
			return ERROR;
		}
		f_close(&MyFile);	  //关闭文件
	}
	else
	{
		safe_printf("Unable to open/create file, please check the SD card or reformat it!\r\n");
		f_close(&MyFile);	  //关闭文件
		return ERROR;
	}

	osDelay(1);
	safe_printf("-------------FatFs File Read Test---------------\r\n");

	BufferSize = sizeof(MyFile_WriteBuffer)/sizeof(BYTE);									// 计算写入的数据长度
	MyFile_Res = f_open(&MyFile,"0:FatFs Test.txt",FA_OPEN_EXISTING | FA_READ);	//打开文件，若不存在则创建该文件
	MyFile_Res = f_lseek(&MyFile, SEEK_SET);									//移动文件指针到开头
	MyFile_Res = f_read(&MyFile,MyFile_ReadBuffer,BufferSize,&MyFile_Num);		// 读取文件
	if(MyFile_Res == FR_OK)
	{
		safe_printf("File read successfully, verifying data...\r\n");

		for(i=0;i<BufferSize;i++)
		{
			if(MyFile_WriteBuffer[i] != MyFile_ReadBuffer[i])		// 校验数据
			{
				safe_printf("Verification failed, please check the SD card or reformat it!\r\nContent written on the card:%s\nContent read:%s\n",MyFile_WriteBuffer,MyFile_ReadBuffer);
				f_close(&MyFile);	  //关闭文件
				return ERROR;
			}
		}
		safe_printf("Verification successful, the data read is:\r\n");
		safe_printf("%s\r\n",MyFile_ReadBuffer);
	}
	else
	{
		safe_printf("Unable to read the file. Please check the SD card or reformat it!\r\n");
		f_close(&MyFile);	  //关闭文件
		return ERROR;
	}

	f_close(&MyFile);	  //关闭文件
	return SUCCESS;
}
/* USER CODE END Application */
